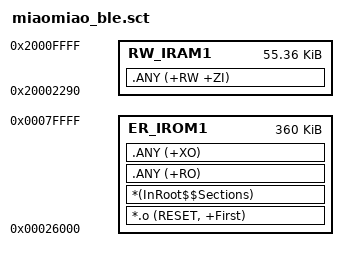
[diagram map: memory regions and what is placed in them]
; ******************************************************************
; *** Scatter-Loading Description File generated by Embedded IDE ***
; ******************************************************************

LR_IROM1 0x00026000 0x0005a000 {
	ER_IROM1 0x00026000 0x0005a000 {
		*.o (RESET, +First) 
		*(InRoot$$Sections) 
		.ANY (+RO) 
		.ANY (+XO) 
	}
	RW_IRAM1 0x20002290 0x0000dd70 {
		.ANY (+RW +ZI) 
	}
}

